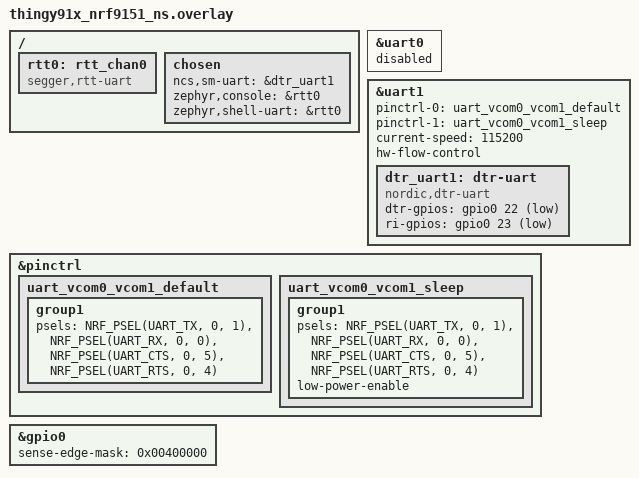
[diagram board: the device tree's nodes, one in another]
/*
 * Copyright (c) 2026 Golioth, Inc.
 *
 * SPDX-License-Identifier: Apache-2.0
 */

/ {
	rtt0: rtt_chan0 {
		compatible = "segger,rtt-uart";
		status = "okay";
	};

	chosen {
		ncs,sm-uart = &dtr_uart1;
		/*
		 * Route console/shell to RTT. The nRF9151's UART0 and UART1
		 * data pins (P0.00/P0.01) are used by the inter-chip
		 * serial-modem link, so UART0 cannot also drive the console.
		 */
		zephyr,console = &rtt0;
		zephyr,shell-uart = &rtt0;
	};
};

/* UART0 is disabled to release P0.00/P0.01 for the modem UART1. */
&uart0 {
	status = "disabled";
};

&uart1 {
	pinctrl-0 = <&uart_vcom0_vcom1_default>;
	pinctrl-1 = <&uart_vcom0_vcom1_sleep>;
	current-speed = <115200>;
	hw-flow-control;
	status = "okay";

	dtr_uart1: dtr-uart {
		compatible = "nordic,dtr-uart";
		dtr-gpios = <&gpio0 22 (GPIO_PULL_DOWN | GPIO_ACTIVE_LOW)>;
		ri-gpios = <&gpio0 23 GPIO_ACTIVE_LOW>;
		status = "okay";
	};
};

&pinctrl {
	uart_vcom0_vcom1_default: uart_vcom0_vcom1_default {
		group1 {
			psels = <NRF_PSEL(UART_TX, 0, 1)>,
				<NRF_PSEL(UART_RX, 0, 0)>,
				<NRF_PSEL(UART_CTS, 0, 5)>,
				<NRF_PSEL(UART_RTS, 0, 4)>;
		};
	};

	uart_vcom0_vcom1_sleep: uart_vcom0_vcom1_sleep {
		group1 {
			psels = <NRF_PSEL(UART_TX, 0, 1)>,
				<NRF_PSEL(UART_RX, 0, 0)>,
				<NRF_PSEL(UART_CTS, 0, 5)>,
				<NRF_PSEL(UART_RTS, 0, 4)>;
			low-power-enable;
		};
	};
};

&gpio0 {
	status = "okay";
	/* Use PORT event for DTR (22) pin to save power */
	sense-edge-mask = <0x00400000>;
};
